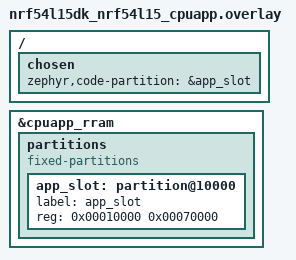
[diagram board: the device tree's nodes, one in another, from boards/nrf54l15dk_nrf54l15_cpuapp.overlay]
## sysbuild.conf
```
# Disable Partition Manager
SB_CONFIG_PARTITION_MANAGER=n
```

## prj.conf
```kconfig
# Link application into /chosen/zephyr,code-partition from devicetree
CONFIG_USE_DT_CODE_PARTITION=y
```

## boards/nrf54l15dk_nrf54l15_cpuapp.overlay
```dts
/ {
    chosen {
        zephyr,code-partition = &app_slot;
    };
};

&cpuapp_rram {

    partitions {
        compatible = "fixed-partitions";
        #address-cells = <1>;
        #size-cells = <1>;

        app_slot: partition@10000 {
            label = "app_slot";
            reg = <0x00010000 0x00070000>;
        };
    };
};
```

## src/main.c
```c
/*
 * Copyright (c) 2012-2014 Wind River Systems, Inc.
 *
 * SPDX-License-Identifier: Apache-2.0
 */

#include <stdio.h>
#include <zephyr/kernel.h>
#include <zephyr/devicetree.h>

/* Getting the Start Address */
#define APP_PARTITION_NODE DT_CHOSEN(zephyr_code_partition)
#define APP_START_ADDRESS DT_REG_ADDR(APP_PARTITION_NODE)

int main(void)
{
	printf("Hello World! %s\n", CONFIG_BOARD_TARGET);
	printf("Running at flash address 0x%08x\n", (uint32_t)APP_START_ADDRESS);

	return 0;
}
```
